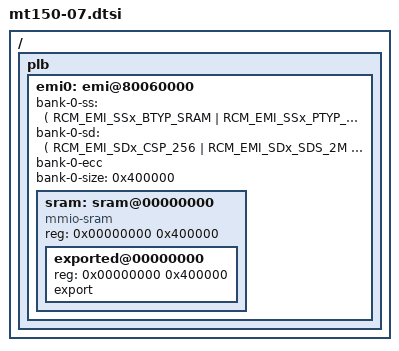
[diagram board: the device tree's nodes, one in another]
/*
 * Device Tree Source for RCM MB115.07 extention board (SRAM)
 *
 * Copyright (C) 2020 MIR
 *	Mikhail.Petrov@mir.dev
 *
 * SPDX-License-Identifier: GPL-2.0+
 */

/ {
	plb {
		emi0: emi@80060000 {
			status = "ok";
			bank-0-ss = <(
				RCM_EMI_SSx_BTYP_SRAM
				| RCM_EMI_SSx_PTYP_NO_PAGES
				| RCM_EMI_SSx_SRDY_EXT_RDY_NOT_USE
				| RCM_EMI_SSx_TWR_0
				| RCM_EMI_SSx_SST_FLOW_THROUGH
				| RCM_EMI_SSx_TSSOE_1
				| RCM_EMI_SSx_TSOE_1
				| RCM_EMI_SSx_TCYC_3
				| RCM_EMI_SSx_RDY(0)
				| RCM_EMI_SSx_TDEL_0)>;
			bank-0-sd = <(
				RCM_EMI_SDx_CSP_256
				| RCM_EMI_SDx_SDS_2M
				| RCM_EMI_SDx_CL_3
				| RCM_EMI_SDx_TRDL_1
				| RCM_EMI_SDx_SI_EXT_INIT
				| RCM_EMI_SDx_T_RCD_5
				| RCM_EMI_SDx_T_RAS_9)>;
			bank-0-ecc;
			bank-0-size = <0x400000>;

			sram: sram@00000000 {
				compatible = "mmio-sram";
				#address-cells = <1>;
				#size-cells = <1>;
				reg = <0x00000000 0x400000>; // 4MB
				ranges = <0x00000000 0x00000000 0x400000>;

				exported@00000000 {
					reg = <0x00000000 0x400000>; // 4MB
					export;
				};
			};
		};
	};
};
